# M4G9 register map
File version: 0.1
Registers are 32-bit, read-write, reset 0x0 unless marked. A register's access mark holds for its fields unless they carry their own. Offsets are from the block's base; [hi:lo] are bit positions; {n}, {i} and the like mark numbered series.

## DNFA — DNF
Base 0x400A0200
Same registers: DNFB 0x400A0300
0x00 CKCR — DNF clock Control register
  [2:0] NFCKS
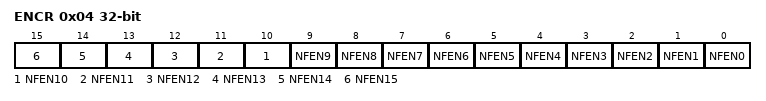
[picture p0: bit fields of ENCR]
0x04 ENCR — DNF Enable register
  [n] NFEN{n} (n=0..15)

## SIWD — Watchdog Timer (WD)
Base 0x400A0600
0x00 PRO reset 0x1E — SIWD Protect Register
  [7:0] PROTECT
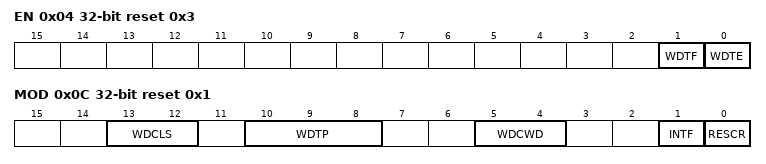
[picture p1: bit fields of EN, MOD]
0x04 EN reset 0x3 — SIWD Enable Register
  [1] WDTF ro, [0] WDTE
0x08 CR wo (reset mask 0xFFFFFF00) — SIWD Control Register
  [7:0] WDCR
0x0C MOD reset 0x1 — SIWD Mode Register
  [13:12] WDCLS, [10:8] WDTP, [5:4] WDCWD, [1] INTF, [0] RESCR
0x10 MONI ro (reset mask 0xC0000000) — SIWD Monitor Register
  [29:0] MONI

## NBD
Base 0x400A2000
0x00 CR0 — NBD control register 0
  [0] NBDEN
0x04 CR1 reset 0x6 — NBD control register 1
  [7:0] NBDCREN

## MDMA — Malti Porpose Direct Memory Accsess(MDMA)
Base 0x400A4000
0x00 REV ro reset 0xFFFFFFFFFFFFFFFF — MDMAC Revision Register
0x04 CEN — MDMAC Channel Enable Register
  [31:0] CHENB
0x08 REQ — MDMAC Transfer Request Register
  [31:0] CHREQ
0x0C SUS — MDMAC Transfer Suspension Register
  [31:0] CHSUS
0x10 ACT — MDMAC Transfer Active Register
  [31:0] CHACT
0x14 END — MDMAC Transfer End Register
  [31:0] CHEND
0x18 PRI — MDMAC Priority Setting Register
  [31:0] CHPRI
0x1C ENE — MDMAC End Interrupt Enable Register
  [31:0] ENDIE
0x20 IAD — MDMAC Channel Information Address Register
  [31:9] CHIAD
0x24 SAD — MDMAC Channel Save Address Register
  [31:10] CHSAD
0x28 CHN ro — MDMAC Channel Number Register
  [3:0] CHNUM
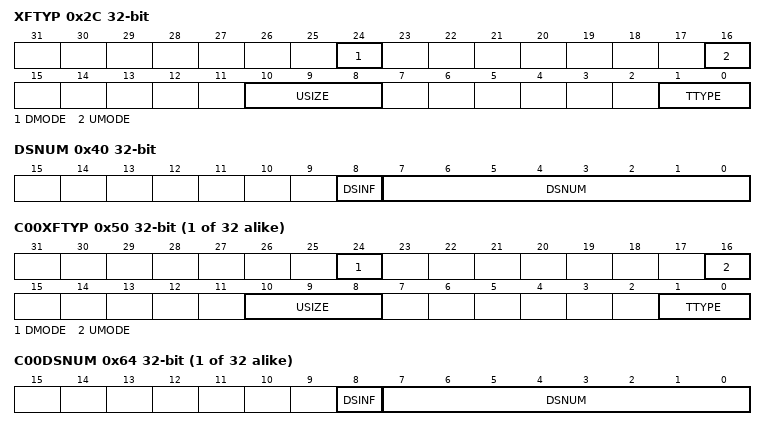
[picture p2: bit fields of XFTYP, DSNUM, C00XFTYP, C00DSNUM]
0x2C XFTYP ro — MDMAC Channel Number Register
  [24] DMODE, [16] UMODE, [10:8] USIZE, [1:0] TTYPE
0x30 XFSAD ro — MDMAC Transfer Source Address Register
  [31:0] SRCAD
0x34 XFDAD ro — MDMAC Transfer Destination Address Register
  [31:0] DSTAD
0x38 XFSIZ ro — MDMAC Transfer Size Register
  [19:0] XFSIZ
0x3C DSADS ro — MDMAC Descriptor Address Register
  [31:2] DSADS
0x40 DSNUM ro — MDMAC Descriptor Number Register
  [8] DSINF, [7:0] DSNUM
0x44 LRQ — MDMAC Level Request Register
  [31:0] LVREQ
{0x50+0x20*i} C{i:02}XFTYP ro (i=0..31) — MDMAC Channel {i:02} Number Avoidance Register
  [24] DMODE, [16] UMODE, [10:8] USIZE, [1:0] TTYPE
{0x54+0x20*i} C{i:02}XFSAD ro (i=0..31) — MDMAC Channel {i:02} Transfer Source Address Avoidance Register
  [31:0] SRCAD
{0x58+0x20*i} C{i:02}XFDAD ro (i=0..31) — MDMAC Channel {i:02} Transfer Destination Address Avoidance Register
  [31:0] DSTAD
{0x5C+0x20*i} C{i:02}XFSIZ ro (i=0..31) — MDMAC Channel {i:02} Transfer Size Avoidance Register
  [19:0] XFSIZ
{0x60+0x20*i} C{i:02}DSADS ro (i=0..31) — MDMAC Channel {i:02} Descriptor Address Avoidance Register
  [31:2] DSADS
{0x64+0x20*i} C{i:02}DSNUM ro (i=0..31) — MDMAC Channel {i:02} Descriptor Number Avoidance Register
  [8] DSINF, [7:0] DSNUM
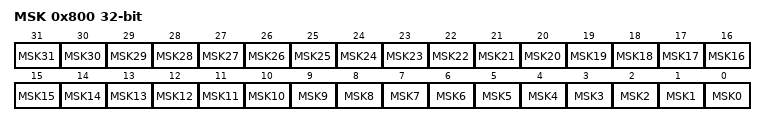
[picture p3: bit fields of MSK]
0x800 MSK — MDMAC Mask Register
  [n] MSK{n} (n=0..31)

## FURT0 — ARM Prime Cell PL011
Base 0x400A8000
Same registers: FURT1 0x400A9000
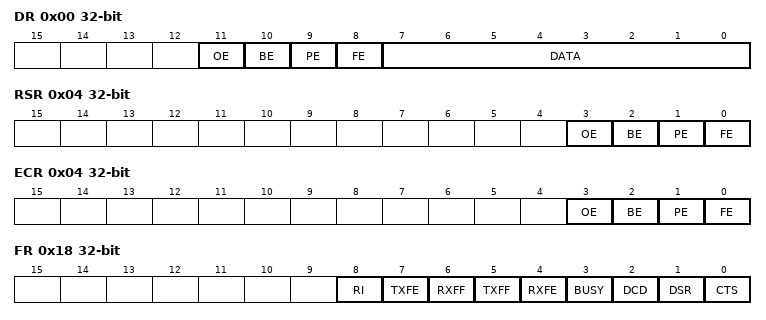
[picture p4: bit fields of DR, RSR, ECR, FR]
0x00 DR — Data Register
  [11] OE ro, [10] BE ro, [9] PE ro, [8] FE ro, [7:0] DATA
0x04 RSR ro — Receive Status Register
  [3] OE, [2] BE, [1] PE, [0] FE
0x04 ECR wo — Error Clear Register
  [3] OE, [2] BE, [1] PE, [0] FE
0x18 FR — Flag Register
  [8] RI, [7] TXFE, [6] RXFF, [5] TXFF, [4] RXFE, [3] BUSY, [2] DCD, [1] DSR, [0] CTS
0x20 ILPR — IrDA Low-power Counter register
  [7:0] IPLDVSR
0x24 IBDR — Integer Baud Rate Register
  [15:0] BAUDDIVINT
0x28 FBDR — Fractional Baud Rate Register
  [5:0] BAUDDIVFRAC
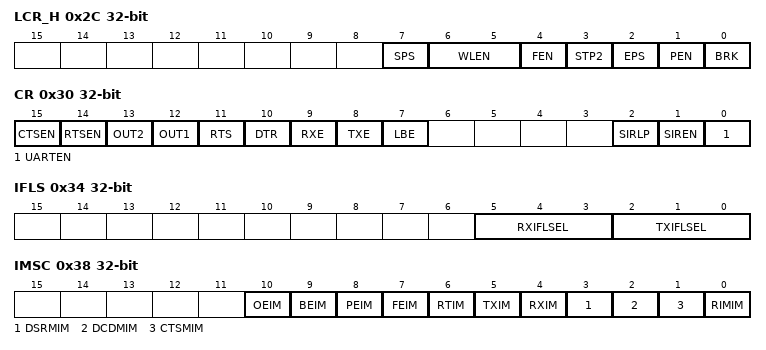
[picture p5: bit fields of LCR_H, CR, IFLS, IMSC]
0x2C LCR_H — Line Control Register
  [7] SPS, [6:5] WLEN, [4] FEN, [3] STP2, [2] EPS, [1] PEN, [0] BRK
0x30 CR — Cntrol Register
  [15] CTSEN, [14] RTSEN, [13] OUT2, [12] OUT1, [11] RTS, [10] DTR, [9] RXE, [8] TXE, [7] LBE, [2] SIRLP, [1] SIREN, [0] UARTEN
0x34 IFLS — Interrupt FIFO Level Select Register
  [5:3] RXIFLSEL, [2:0] TXIFLSEL
0x38 IMSC — Interrupt Mask set_Clear Register
  [10] OEIM, [9] BEIM, [8] PEIM, [7] FEIM, [6] RTIM, [5] TXIM, [4] RXIM, [3] DSRMIM, [2] DCDMIM, [1] CTSMIM, [0] RIMIM
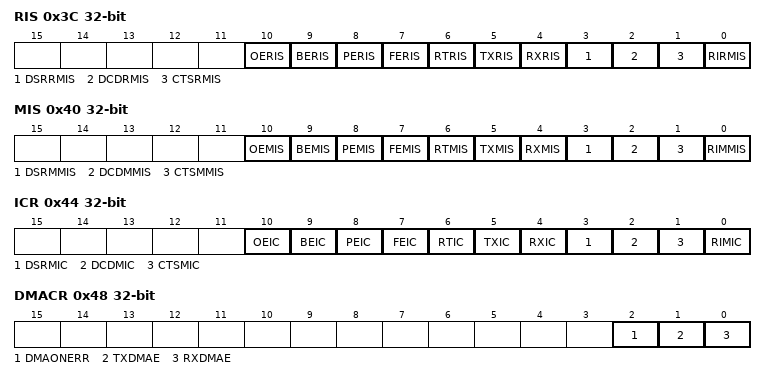
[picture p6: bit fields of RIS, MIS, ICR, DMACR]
0x3C RIS ro (reset mask 0xFFFFFFF0) — Raw Interrupt Status Register
  [10] OERIS, [9] BERIS, [8] PERIS, [7] FERIS, [6] RTRIS, [5] TXRIS, [4] RXRIS, [3] DSRRMIS, [2] DCDRMIS, [1] CTSRMIS, [0] RIRMIS
0x40 MIS ro (reset mask 0xFFFFFFF0) — Masked Interrupt Status Register
  [10] OEMIS, [9] BEMIS, [8] PEMIS, [7] FEMIS, [6] RTMIS, [5] TXMIS, [4] RXMIS, [3] DSRMMIS, [2] DCDMMIS, [1] CTSMMIS, [0] RIMMIS
0x44 ICR wo — Interrupt Clear Register
  [10] OEIC, [9] BEIC, [8] PEIC, [7] FEIC, [6] RTIC, [5] TXIC, [4] RXIC, [3] DSRMIC, [2] DCDMIC, [1] CTSMIC, [0] RIMIC
0x48 DMACR — DMA Control Register
  [2] DMAONERR, [1] TXDMAE, [0] RXDMAE
